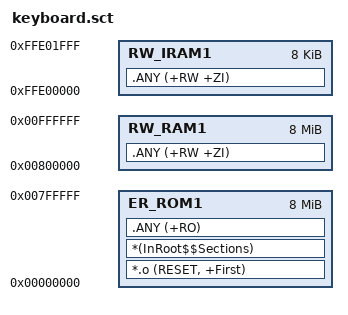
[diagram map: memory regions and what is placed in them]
; *************************************************************
; *** Scatter-Loading Description File generated by uVision ***
; *************************************************************

LR_ROM1 0x00000000 0x00800000  {    ; load region size_region
  ER_ROM1 0x00000000 0x00800000  {  ; load address = execution address
   *.o (RESET, +First)
   *(InRoot$$Sections)
   .ANY (+RO)
  }
  RW_RAM1 0x00800000 0x00800000  {  ; RW data
   .ANY (+RW +ZI)
  }
  RW_IRAM1 0xFFE00000 0x00002000  {
   .ANY (+RW +ZI)
  }
}

